# DA1470x register map
Vendor: Dialog; Series: DA1470x; File version: 1.2
CPU: CM33 r0p2, little endian, MPU, FPU, DSP, VTOR, 4 interrupt priority bits
Registers are 32-bit, read-write, reset 0x0 unless marked. A register's access mark holds for its fields unless they carry their own. Offsets are from the block's base; [hi:lo] are bit positions; {n}, {i} and the like mark numbered series; <NAME> marks a mode.

## GPU_CORE — GPU_CORE registers
Base 0x51001200
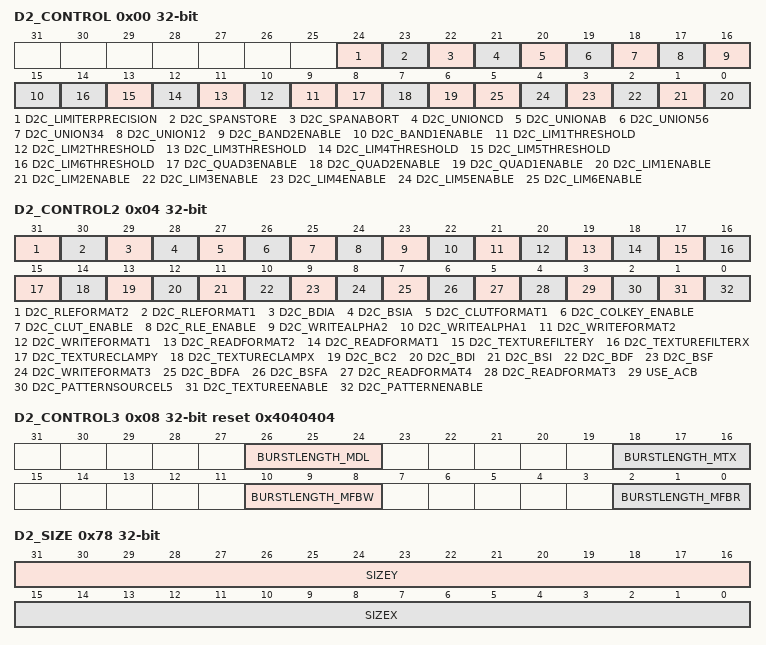
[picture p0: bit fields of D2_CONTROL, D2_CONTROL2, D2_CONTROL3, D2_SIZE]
0x00 D2_CONTROL — #0: geometry control register This register controls the pixel enumeration and selection units, deciding which pixels are
  [24] D2C_LIMITERPRECISION wo — increase precision of limiters from 16.16 to 10.22
  [23] D2C_SPANSTORE wo — nextline span start is always equal or left to current-line span start
  [22] D2C_SPANABORT wo — shape is horizontally convex. only a single span per scanline
  [21] D2C_UNIONCD wo — combine outputs C & D as union (output is final)
  [20] D2C_UNIONAB wo — combine outputs A & B as union (output is called C)
  [19] D2C_UNION56 wo — combine limter 5 & 6 as union (output is called D)
  [18] D2C_UNION34 wo — combine limter 3 & 4 as union (output is called B)
  [17] D2C_UNION12 wo — combine limter 1 & 2 as union (output is called A)
  [16] D2C_BAND2ENABLE wo — enable band postprocess for limiter 2 (see <D2_L2BAND>)
  [15] D2C_BAND1ENABLE wo — enable band postprocess for limiter 1 (see <D2_L1BAND>)
  [n+8] D2C_LIM{n}THRESHOLD wo (n=1..6) — enable limiter {n} threshold mode
  [8] D2C_QUAD3ENABLE wo — enable quadratic coupling of limiters 5 and 6
  [7] D2C_QUAD2ENABLE wo — enable quadratic coupling of limiters 3 and 4
  [6] D2C_QUAD1ENABLE wo — enable quadratic coupling of limiters 1 and 2
  [n-1] D2C_LIM{n}ENABLE wo (n=1..6) — enable limiter {n}
0x04 D2_CONTROL2 (reset mask 0x7FFFFFFF) — #1: surface control register This register controls the colorization, texturing and blending units, deciding what color a p
  [31] D2C_RLEFORMAT2 wo — bit1 of RLE texel format
  [30] D2C_RLEFORMAT1 wo — bit0 of RLE texel format
  [29] D2C_BDIA wo — dst factor for alpha channel will be inverted (meaning 1-a or 1-1 depending on BDFA)
  [28] D2C_BSIA wo — src factor for alpha channel will be inverted (meaning 1-a or 1-1 depending on BSFA)
  [27] D2C_CLUTFORMAT1 wo — bit0 of the CLUT entry format
  [26] D2C_COLKEY_ENABLE wo — enable color keying (see also <D2_COLKEY> and feature bits of <D2_HWREVISION>)
  [25] D2C_CLUT_ENABLE wo — enable the use of the CLUT (see also feature bits of <D2_HWREVISION>); if disabled the texture indices are written to FB
  [24] D2C_RLE_ENABLE wo — enable RLE decoder (see also feature bits of <D2_HWREVISION>)
  [23] D2C_WRITEALPHA2 wo — bit1 of the 'alpha source' (depends on USE_ACB)
  [22] D2C_WRITEALPHA1 wo — bit0 of the 'alpha source' (depends on USE_ACB)
  [21] D2C_WRITEFORMAT2 wo — bit1 of the framebuffer format descriptor
  [20] D2C_WRITEFORMAT1 wo — bit0 of the framebuffer format descriptor
  [19] D2C_READFORMAT2 wo — bit1 of the texture format descriptor
  [18] D2C_READFORMAT1 wo — bit0 of the texture format descriptor
  [17] D2C_TEXTUREFILTERY wo — linear filtering on texture v axis
  [16] D2C_TEXTUREFILTERX wo — linear filtering on texture u axis
  [15] D2C_TEXTURECLAMPY wo — clamp instead of mask v coordinate
  [14] D2C_TEXTURECLAMPX wo — clamp instead of mask u coordinate
  [13] D2C_BC2 wo — blending for color channels is done with <D2_COLOR2> instead of the real dst value
  [12] D2C_BDI wo — dst factor for color channels will be inverted (meaning 1-a or 1-1 depending on BDF)
  [11] D2C_BSI wo — src factor for color channels will be inverted (meaning 1-a or 1-1 depending on BSF)
  [10] D2C_BDF wo — dst factor for color channels is alpha (factor is 1 per default)
  [9] D2C_BSF wo — src factor for color channels is alpha (factor is 1 per default)
  [8] D2C_WRITEFORMAT3 wo — bit2 of the framebuffer format descriptor
  [7] D2C_BDFA wo — dst factor for alpha channel is alpha (factor is 1 per default)
  [6] D2C_BSFA wo — src factor for alpha channel is alpha (factor is 1 per default)
  [5] D2C_READFORMAT4 wo — bit3 of the texture format descriptor
  [4] D2C_READFORMAT3 wo — bit2 of the texture format descriptor
  [3] USE_ACB wo — use full alpha channel blending, else use write-alpha mode
  [2] D2C_PATTERNSOURCEL5 wo — Limiter 5 is used as pattern index instead of the default U-Limiter
  [1] D2C_TEXTUREENABLE wo — Pixel source is read from texture and used as an alpha to blend between <D2_COLOR1> and <D2_COLOR2>
  [0] D2C_PATTERNENABLE wo — Pixel source is a pattern color (blend of <D2_COLOR1> and <D2_COLOR2> depending on <D2_PATTERN> and pattern index)
0x08 D2_CONTROL3 reset 0x4040404 — #2: burst length limit control register This register controls the burst length limit for the master bus interfaces Log2 of
  [26:24] BURSTLENGTH_MDL wo — Log2 of the burst length limit for MDL read
  [18:16] BURSTLENGTH_MTX wo — Log2 of the burst length limit for MTX read
  [10:8] BURSTLENGTH_MFBW wo — Log2 of the burst length limit for MFB write
  [2:0] BURSTLENGTH_MFBR wo — Log2 of the burst length limit for MFB read
0x10 D2_L1START (reset mask 0x7FFFFFFF) — #4: Limiter1 start value All limiter registers are *write only*, reading will return undefined results. Limiters must be ena
  [31:0] L1START wo
{0xC+4i} D2_L{i}START (reset mask 0x7FFFFFFF) (i=2..6) — #{i+3}: Limiter{i} start value see <D2_L1START>
  [31:0] L{i}START wo
0x28 D2_L1XADD (reset mask 0x7FFFFFFF) — #10: Limiter1 X-Axis increment The xadd value is the 16:16 fixedpoint difference between two samples with a distance of 1 pix
  [31:0] L1XADD wo
0x2C D2_L2XADD (reset mask 0x7FFFFFFF) — #11: Limiter2 X-Axis increment see <D2_L1XADD>
  [31:0] L2XADD wo
0x30 D2_L3XADD (reset mask 0x7FFFFFFF) — #12: Limiter3 X-Axis increment
  [31:0] L3XADD wo
{0x24+4i} D2_L{i}XADD (reset mask 0x7FFFFFFF) (i=4..6) — #{i+9}: Limiter{i} X-Axis increment see <D2_L1XADD>
  [31:0] L{i}XADD wo
0x40 D2_L1YADD (reset mask 0x7FFFFFFF) — #16: Limiter1 Y-Axis increment The yadd value is the 16:16 fixedpoint difference between two samples with a distance of 1 pix
  [31:0] L1YADD wo
{0x3C+4i} D2_L{i}YADD (reset mask 0x7FFFFFFF) (i=2..6) — #{i+15}: Limiter{i} Y-Axis increment see <D2_L1YADD>
  [31:0] L{i}YADD wo
0x58 D2_L1BAND (reset mask 0x7FFFFFFF) — #22: Limiter1 band width parameter Postfilter First two limiter outputs can be routed through an additional unit before cla
  [31:0] L1BAND wo
0x5C D2_L2BAND (reset mask 0x7FFFFFFF) — #23: Limiter2 band width parameter see <D2_L1BAND>
  [31:0] L2BAND wo
0x64 D2_COLOR1 (reset mask 0x7FFFFFFF) — #25: Base color register All color registers are *write only*, reading will return undefined results. When using textures th
  [31:0] COLOR1 wo
0x68 D2_COLOR2 (reset mask 0x7FFFFFFF) — #26: Secondary color register Secondary color is relevant only when rendering patterns, textures or using a D2C_BC2 blendmod
  [31:0] COLOR2 wo
0x74 D2_PATTERN (reset mask 0x7FFFFFFF) — #29: Pattern register Each bit in the pattern register is interpreted as a reference to one of the two color registers ( 0bi
  [31:0] PATTERN wo
0x78 D2_SIZE (reset mask 0x7FFFFFFF) — #30: bounding box dimension
  [31:16] SIZEY wo — the height (in pixels) of the primitives bounding box.
  [15:0] SIZEX wo — the width (in pixels) of the primitives bounding box.
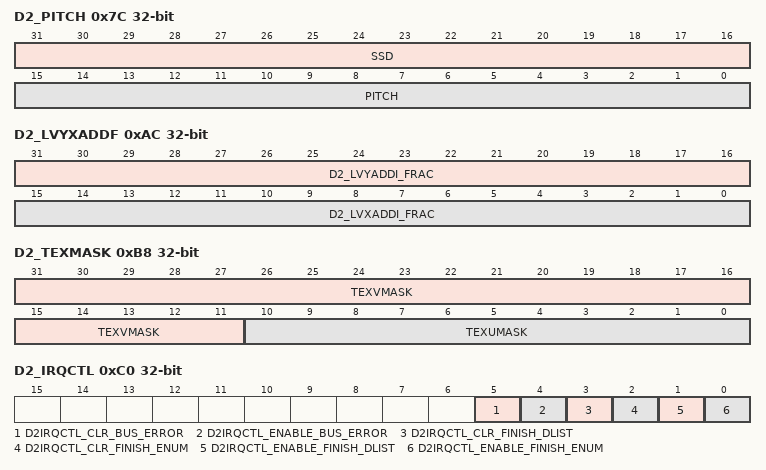
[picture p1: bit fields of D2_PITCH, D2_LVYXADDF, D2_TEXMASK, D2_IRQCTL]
0x7C D2_PITCH (reset mask 0x7FFFFFFF) — #31: framebuffer pitch and spanstore delay
  [31:16] SSD wo — spanstore delay, the number of scanlines to delay spanstore operations.
  [15:0] PITCH wo — the width (in pixels) of one framebuffer scanline. A negative width can be used to render bottom-up instead of top-down.
0x80 D2_ORIGIN (reset mask 0x7FFFFFFF) — #32: address of the first pixel in framebuffer Writing to <D2_ORIGIN> will *trigger* DAVE2 to start rendering.
  [31:0] ORIGIN wo
0x90 D2_LUSTART (reset mask 0x7FFFFFFF) — #36: U Limiter start value The start value is a 16:16 fixedpoint number valid at the first pixel of the bounding box.
  [31:0] LUSTART wo
0x94 D2_LUXADD (reset mask 0x7FFFFFFF) — #37: U Limiter X-Axis increment The add value for U is the 16:16 fixedpoint difference between two samples with a distance o
  [31:0] LUXADD wo
0x98 D2_LUYADD (reset mask 0x7FFFFFFF) — #38: U Limiter Y-Axis increment The add value for U is the 16:16 fixedpoint difference between two samples with a distance o
  [31:0] LUYADD wo
0x9C D2_LVSTARTI (reset mask 0x7FFFFFFF) — #39: V Limiter start value integer part
  [31:0] LVSTARTI wo
0xA0 D2_LVSTARTF — #40: V Limiter start value fractional part The start value is a 32:16 fixedpoint number valid at the first pixel of the boun
  [15:0] LVSTARTF wo — fractional part.
0xA4 D2_LVXADDI (reset mask 0x7FFFFFFF) — #41: V Limiter X-Axis increment integer part The add value for V is the 32:16 fixedpoint difference between two samples with
  [31:0] LVXADDI wo
0xA8 D2_LVYADDI (reset mask 0x7FFFFFFF) — #42: V Limiter Y-Axis increment integer part The add value for V is the 32:16 fixedpoint difference between two samples with
  [31:0] LVYADDI wo
0xAC D2_LVYXADDF (reset mask 0x7FFFFFFF) — #43: V Limiter X and Y increment fractional parts
  [31:16] D2_LVYADDI_FRAC wo — Y increment fractional part for <D2_LVYADDI>.
  [15:0] D2_LVXADDI_FRAC wo — X increment fractional part for <D2_LVXADDI>.
0xB4 D2_TEXPITCH (reset mask 0x7FFFFFFF) — #45: Texels per texture line Pitch is equal or bigger than texture width.
  [31:0] TEXPITCH wo
0xB8 D2_TEXMASK (reset mask 0x7FFFFFFF) — #46: Texture size or texture address mask Depending on the clamping mode this register encodes the clamp limit or wrap mask.
  [31:11] TEXVMASK wo — V mask.
  [10:0] TEXUMASK wo — U mask.
0xBC D2_TEXORIGIN (reset mask 0x7FFFFFFF) — #47: Texture base address All texture registers are *write only*, reading will return undefined results. Patterns and textur
  [31:0] TEXORIGIN wo
0xC0 D2_IRQCTL — #48: interrupt control register DAVE2 features three sources for interrupts. They can be enabled and cleared individually.
  [5] D2IRQCTL_CLR_BUS_ERROR wo — Clear Interrupt 'Bus error'
  [4] D2IRQCTL_ENABLE_BUS_ERROR wo — Interruptmask enable 'Bus error'
  [3] D2IRQCTL_CLR_FINISH_DLIST wo — Clear Interrupt 'Displaylist is finished'. Make sure to clear the IRQ before starting the DLR again! No register writes must be done by the CPU while the DLR is active!
  [2] D2IRQCTL_CLR_FINISH_ENUM wo — Clear Interrupt 'Enumeration is finished'
  [1] D2IRQCTL_ENABLE_FINISH_DLIST wo — Interruptmask enable 'Displaylist is finished'
  [0] D2IRQCTL_ENABLE_FINISH_ENUM wo — Interruptmask enable 'Enumeration is finished'
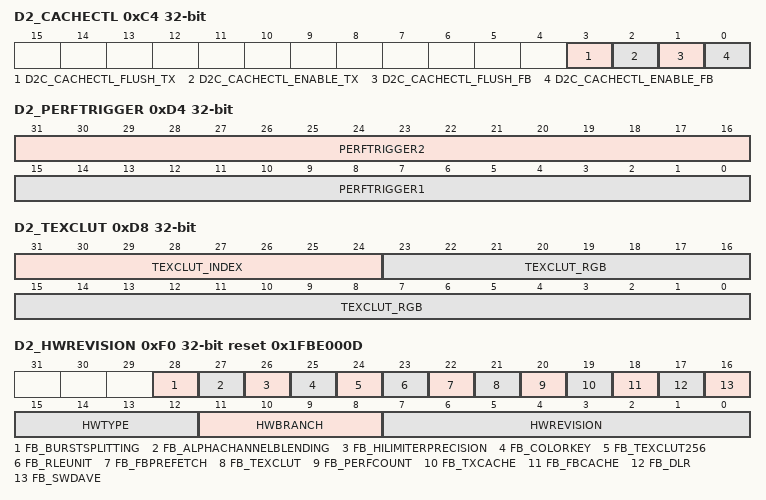
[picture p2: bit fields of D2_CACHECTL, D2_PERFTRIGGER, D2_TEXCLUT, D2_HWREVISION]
0xC4 D2_CACHECTL — #49: cache control register Internal caches can be enabled/disabled and flushed using this register. Note that caches will b
  [3] D2C_CACHECTL_FLUSH_TX wo — Flush texture cache
  [2] D2C_CACHECTL_ENABLE_TX wo — Texture cache enable
  [1] D2C_CACHECTL_FLUSH_FB wo — Flush framebuffer cache
  [0] D2C_CACHECTL_ENABLE_FB wo — Framebuffer cache enable
0xC8 D2_DLISTSTART (reset mask 0x7FFFFFFF) — #50: Displaylist start address Setting a new displaylist base address (writing to D2_DLISTSTART) *triggers* execution of th
  [31:0] DLISTSTART wo
0xCC D2_PERFCOUNT1 (reset mask 0x7FFFFFFF) — #51: Performance counter Writing to the D2_PERFCOUNT1 register resets the first internal performance counter to the specifie
0xD0 D2_PERFCOUNT2 (reset mask 0x7FFFFFFF) — #52: Performance counter Writing to the D2_PERFCOUNT2 register resets the second internal performance counter to the specifi
0xD4 D2_PERFTRIGGER (reset mask 0x7FFFFFFF) — #53: Performance counters control register Select the internal event that will increment <D2_PERFCOUNT1> respectively &
  [31:16] PERFTRIGGER2 wo — Select the internal event that will increment D2_PERFCOUNT2 register.
  [15:0] PERFTRIGGER1 wo — Select the internal event that will increment D2_PERFCOUNT1 register.
0xD8 D2_TEXCLUT (reset mask 0x7FFFFFFF) — #54: Color Lookup Table for the indexed texture format 16x24bit Triggers a write into the CLUT if CLUT size is 16 x 24bit.
  [31:24] TEXCLUT_INDEX wo — Index of the CLUT entry, that shall be written
  [23:0] TEXCLUT_RGB wo — Color Value RGB888
0xDC D2_TEXCLUT_ADDR — #55: Color Lookup Table write address for the indexed texture format 256x32bit Start address for consecutive writes to <D2
  [7:0] TEXCLUT_ADDR wo — write address
0xE0 D2_TEXCLUT_DATA (reset mask 0x7FFFFFFF) — #56: Color Lookup Table write data for the indexed texture format 256x32bit Writes one 32 bit color value into the CLUT if CL
  [31:0] TEXCLUT_ARGB wo — Color value ARGB8888 if CLUTFORMAT = argb8888
0xE4 D2_TEXCLUT_OFFSET — #57: Offset to the texture index for the indexed texture formats i8, i4, i2 and i1 The index offset is combined with the text
  [7:0] TEXCLUT_OFFSET wo — index offset
0xE8 D2_COLKEY — #58: Color key value The R, G and B components of the internal color representation of a texel is compared with the color key
  [23:0] COLKEY_RGB wo — Color Key Value RGB888
0xF0 D2_HWREVISION reset 0x1FBE000D — #1: hardware version and feature set ID Read this (constant) register to identify the present hardware revision and feature
  [28] FB_BURSTSPLITTING ro — bursts can be split with respect to burst length limit
  [27] FB_ALPHACHANNELBLENDING ro — full alpha channel blending available
  [26] FB_HILIMITERPRECISION ro — increasable precision of limiters available
  [25] FB_COLORKEY ro — color keying available
  [24] FB_TEXCLUT256 ro — extend CLUT to 256x32bit ARGB8888
  [23] FB_RLEUNIT ro — RLE texture decoder available
  [22] FB_FBPREFETCH ro — Framebuffer prefetch available
  [21] FB_TEXCLUT ro — Color Lookup Table 16x24bit for indexed textureformat available
  [20] FB_PERFCOUNT ro — Two performance counters available
  [19] FB_TXCACHE ro — Texture Cache available
  [18] FB_FBCACHE ro — Framebuffer Cache available
  [17] FB_DLR ro — DisplayListReader available
  [16] FB_SWDAVE ro — Software D/AVE
  [15:12] HWTYPE ro — D/AVE Type
  [11:8] HWBRANCH ro — Branch number
  [7:0] HWREVISION ro — Revision number
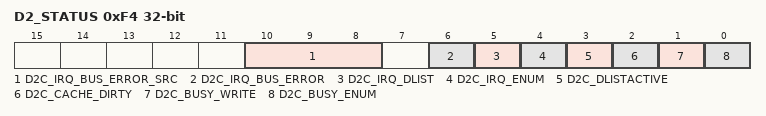
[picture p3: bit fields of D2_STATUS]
0xF4 D2_STATUS — #0: status control register The current dave status can be polled by reading this register. It contains a combination of th
  [10:8] D2C_IRQ_BUS_ERROR_SRC ro — source interface of bus error
  [6] D2C_IRQ_BUS_ERROR ro — IRQ on bus error
  [5] D2C_IRQ_DLIST ro — IRQ on display list finish
  [4] D2C_IRQ_ENUM ro — IRQ on enumeration finish
  [3] D2C_DLISTACTIVE ro — display list active, cant direct access hwregs
  [2] D2C_CACHE_DIRTY ro — framebuffer cache dirty, cant flip frame
  [1] D2C_BUSY_WRITE ro — framebuffer writeback busy, cant change framebuffer type
  [0] D2C_BUSY_ENUM ro — enumeration unit busy, cant start new primitive
